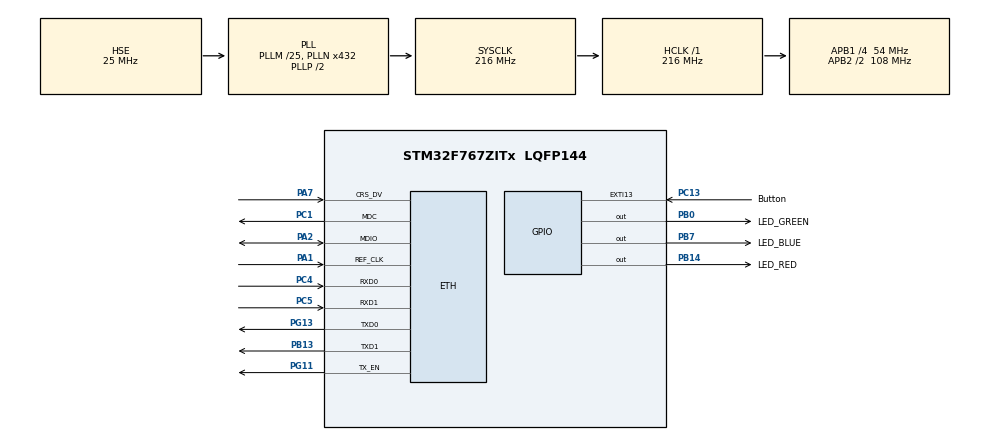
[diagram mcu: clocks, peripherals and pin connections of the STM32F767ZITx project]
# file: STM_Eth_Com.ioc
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ETH.MACAddr=00\:80\:E2\:00\:00\:00
ETH.MediaInterface=ETH_MEDIA_INTERFACE_RMII
ETH.PhyAddress=0
LWIP.LWIP_DHCP=0
LWIP.Version=v2.1.2_Cube
Mcu.Family=STM32F7
Mcu.Name=STM32F767ZITx
Mcu.Package=LQFP144
NVIC.EXTI15_10_IRQn=true\:0\:0\:false\:false\:true\:true\:true
NVIC.PriorityGroup=NVIC_PRIORITYGROUP_4
PA1.Mode=RMII
PA1.Signal=ETH_REF_CLK
PA13.Mode=Serial_Wire
PA13.Signal=SYS_JTMS-SWDIO
PA14.Mode=Serial_Wire
PA14.Signal=SYS_JTCK-SWCLK
PA2.Mode=RMII
PA2.Signal=ETH_MDIO
PA7.Mode=RMII
PA7.Signal=ETH_CRS_DV
PB0.GPIO_Label=LED_GREEN
PB0.Signal=GPIO_Output
PB13.Mode=RMII
PB13.Signal=ETH_TXD1
PB14.GPIO_Label=LED_RED
PB14.Signal=GPIO_Output
PB7.GPIO_Label=LED_BLUE
PB7.Signal=GPIO_Output
PC1.Mode=RMII
PC1.Signal=ETH_MDC
PC13.GPIO_Label=Button
PC13.GPIO_ModeDefaultEXTI=GPIO_MODE_IT_FALLING
PC13.Signal=GPXTI13
PC4.Mode=RMII
PC4.Signal=ETH_RXD0
PC5.Mode=RMII
PC5.Signal=ETH_RXD1
PG11.Mode=RMII
PG11.Signal=ETH_TX_EN
PG13.Mode=RMII
PG13.Signal=ETH_TXD0
PH0/OSC_IN.Mode=HSE-External-Oscillator
PH0/OSC_IN.Signal=RCC_OSC_IN
PH1/OSC_OUT.Mode=HSE-External-Oscillator
PH1/OSC_OUT.Signal=RCC_OSC_OUT
ProjectManager.HeapSize=0x200
ProjectManager.StackSize=0x400
ProjectManager.TargetToolchain=STM32CubeIDE
RCC.AHBFreq_Value=216000000
RCC.APB1CLKDivider=RCC_HCLK_DIV4
RCC.APB1Freq_Value=54000000
RCC.APB1TimFreq_Value=108000000
RCC.APB2CLKDivider=RCC_HCLK_DIV2
RCC.APB2Freq_Value=108000000
RCC.APB2TimFreq_Value=216000000
RCC.CortexFreq_Value=216000000
RCC.HCLKFreq_Value=216000000
RCC.HSE_VALUE=25000000
RCC.HSI_VALUE=16000000
RCC.LSE_VALUE=32768
RCC.PLLM=25
RCC.PLLN=432
RCC.PLLSourceVirtual=RCC_PLLSOURCE_HSE
RCC.SYSCLKFreq_VALUE=216000000
RCC.SYSCLKSource=RCC_SYSCLKSOURCE_PLLCLK
RCC.USBFreq_Value=216000000
RCC.VCOOutputFreq_Value=432000000
VP_LWIP_VS_Enabled.Mode=Enabled
board=custom

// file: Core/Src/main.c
/* USER CODE BEGIN Header */
/**
  ******************************************************************************
  * @file           : main.c
  * @brief          : Main program body
  ******************************************************************************
  * @attention
  *
  * Copyright (c) 2021 STMicroelectronics.
  * All rights reserved.
  *
  * This software is licensed under terms that can be found in the LICENSE file
  * in the root directory of this software component.
  * If no LICENSE file comes with this software, it is provided AS-IS.
  *
  ******************************************************************************
  */
/* USER CODE END Header */
#include "main.h"
#include "lwip.h"
#include "gpio.h"

/* USER CODE BEGIN Includes */
#include "Eth_API.h"
/* USER CODE END Includes */

/* USER CODE BEGIN PV */
static const eth_address destination = {0xD0, 0x03, 0xEB, 0x27, 0xB8, 0xEE};
//static const eth_address destination = { 0x00, 0x80, 0xE2, 0x00, 0x00, 0x00};
/* USER CODE END PV */

void SystemClock_Config(void);

int main(void)
{

  /* MCU Configuration--------------------------------------------------------*/

  /* Reset of all peripherals, Initializes the Flash interface and the Systick. */
  HAL_Init();

  /* Configure the system clock */
  SystemClock_Config();

  /* Initialize all configured peripherals */
  MX_GPIO_Init();
  MX_LWIP_Init();

  /* Infinite loop */
  while (1)
  {
	  ETH_Proccess();

  }
}

void SystemClock_Config(void)
{
  RCC_OscInitTypeDef RCC_OscInitStruct = {0};
  RCC_ClkInitTypeDef RCC_ClkInitStruct = {0};

  /** Configure the main internal regulator output voltage
  */
  __HAL_RCC_PWR_CLK_ENABLE();
  __HAL_PWR_VOLTAGESCALING_CONFIG(PWR_REGULATOR_VOLTAGE_SCALE1);
  /** Initializes the RCC Oscillators according to the specified parameters
  * in the RCC_OscInitTypeDef structure.
  */
  RCC_OscInitStruct.OscillatorType = RCC_OSCILLATORTYPE_HSE;
  RCC_OscInitStruct.HSEState = RCC_HSE_ON;
  RCC_OscInitStruct.PLL.PLLState = RCC_PLL_ON;
  RCC_OscInitStruct.PLL.PLLSource = RCC_PLLSOURCE_HSE;
  RCC_OscInitStruct.PLL.PLLM = 25;
  RCC_OscInitStruct.PLL.PLLN = 432;
  RCC_OscInitStruct.PLL.PLLP = RCC_PLLP_DIV2;
  RCC_OscInitStruct.PLL.PLLQ = 2;
  RCC_OscInitStruct.PLL.PLLR = 2;
  if (HAL_RCC_OscConfig(&RCC_OscInitStruct) != HAL_OK)
  {
    Error_Handler();
  }
  /** Activate the Over-Drive mode
  */
  if (HAL_PWREx_EnableOverDrive() != HAL_OK)
  {
    Error_Handler();
  }
  /** Initializes the CPU, AHB and APB buses clocks
  */
  RCC_ClkInitStruct.ClockType = RCC_CLOCKTYPE_HCLK|RCC_CLOCKTYPE_SYSCLK
                              |RCC_CLOCKTYPE_PCLK1|RCC_CLOCKTYPE_PCLK2;
  RCC_ClkInitStruct.SYSCLKSource = RCC_SYSCLKSOURCE_PLLCLK;
  RCC_ClkInitStruct.AHBCLKDivider = RCC_SYSCLK_DIV1;
  RCC_ClkInitStruct.APB1CLKDivider = RCC_HCLK_DIV4;
  RCC_ClkInitStruct.APB2CLKDivider = RCC_HCLK_DIV2;

  if (HAL_RCC_ClockConfig(&RCC_ClkInitStruct, FLASH_LATENCY_7) != HAL_OK)
  {
    Error_Handler();
  }
}

/* USER CODE BEGIN 4 */
void HAL_GPIO_EXTI_Callback(uint16_t GPIO_Pin)
{
	if(Button_Pin == GPIO_Pin)
	{
		const uint8_t data[] = {0x01,0xAC, 0x7B, 0xFF, 0x12};
		ETH_Send_data(destination, data, GET_ARRAY_SIZE(data));
	}
}
/* USER CODE END 4 */

void Error_Handler(void)
{
  __disable_irq();
  while (1)
  {
  }
}
